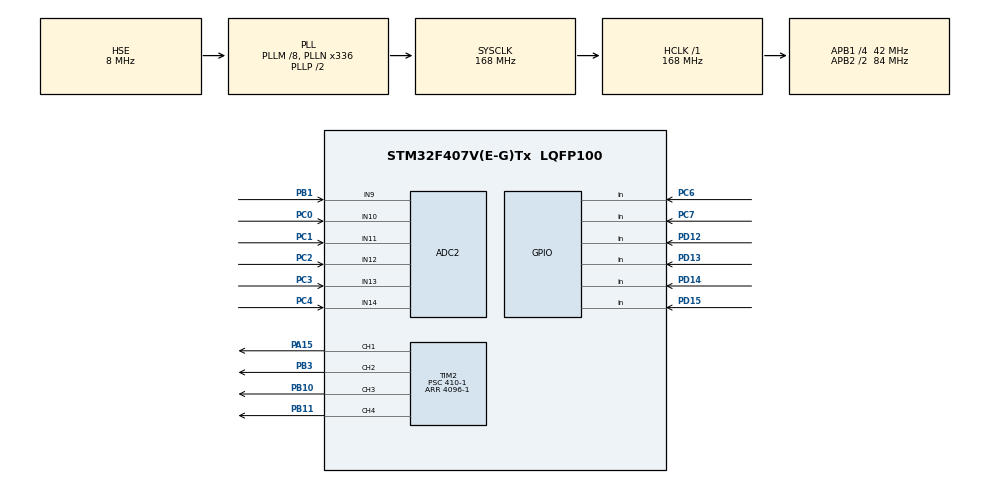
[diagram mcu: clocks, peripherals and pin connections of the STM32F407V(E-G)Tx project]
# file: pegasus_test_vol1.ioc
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ADC2.Channel-1\#ChannelRegularConversion=ADC_CHANNEL_14
ADC2.Channel-2\#ChannelRegularConversion=ADC_CHANNEL_13
ADC2.Channel-3\#ChannelRegularConversion=ADC_CHANNEL_12
ADC2.Channel-4\#ChannelRegularConversion=ADC_CHANNEL_11
ADC2.Channel-5\#ChannelRegularConversion=ADC_CHANNEL_10
ADC2.Channel-6\#ChannelRegularConversion=ADC_CHANNEL_9
ADC2.ContinuousConvMode=DISABLE
ADC2.DMAContinuousRequests=ENABLE
ADC2.DiscontinuousConvMode=DISABLE
ADC2.NbrOfConversion=6
ADC2.NbrOfConversionFlag=1
ADC2.Rank-1\#ChannelRegularConversion=1
ADC2.Rank-2\#ChannelRegularConversion=2
ADC2.Rank-3\#ChannelRegularConversion=3
ADC2.Rank-4\#ChannelRegularConversion=4
ADC2.Rank-5\#ChannelRegularConversion=5
ADC2.Rank-6\#ChannelRegularConversion=6
ADC2.SamplingTime-1\#ChannelRegularConversion=ADC_SAMPLETIME_3CYCLES
ADC2.SamplingTime-2\#ChannelRegularConversion=ADC_SAMPLETIME_3CYCLES
ADC2.SamplingTime-3\#ChannelRegularConversion=ADC_SAMPLETIME_3CYCLES
ADC2.SamplingTime-4\#ChannelRegularConversion=ADC_SAMPLETIME_3CYCLES
ADC2.SamplingTime-5\#ChannelRegularConversion=ADC_SAMPLETIME_3CYCLES
ADC2.SamplingTime-6\#ChannelRegularConversion=ADC_SAMPLETIME_3CYCLES
ADC2.ScanConvMode=ENABLE
Dma.ADC2.0.Direction=DMA_PERIPH_TO_MEMORY
Dma.ADC2.0.FIFOMode=DMA_FIFOMODE_DISABLE
Dma.ADC2.0.Instance=DMA2_Stream2
Dma.ADC2.0.MemDataAlignment=DMA_MDATAALIGN_WORD
Dma.ADC2.0.MemInc=DMA_MINC_ENABLE
Dma.ADC2.0.Mode=DMA_NORMAL
Dma.ADC2.0.PeriphDataAlignment=DMA_PDATAALIGN_WORD
Dma.ADC2.0.PeriphInc=DMA_PINC_DISABLE
Dma.ADC2.0.Priority=DMA_PRIORITY_LOW
Dma.Request0=ADC2
Mcu.Family=STM32F4
Mcu.Name=STM32F407V(E-G)Tx
Mcu.Package=LQFP100
NVIC.DMA2_Stream2_IRQn=true\:0\:0\:false\:false\:true\:false\:true\:true
NVIC.PriorityGroup=NVIC_PRIORITYGROUP_0
PA13.Mode=Serial_Wire
PA13.Signal=SYS_JTMS-SWDIO
PA14.Mode=Serial_Wire
PA14.Signal=SYS_JTCK-SWCLK
PA15.Signal=S_TIM2_CH1_ETR
PB1.Signal=ADCx_IN9
PB10.Signal=S_TIM2_CH3
PB11.Signal=S_TIM2_CH4
PB3.Signal=S_TIM2_CH2
PC0.Signal=ADCx_IN10
PC1.Signal=ADCx_IN11
PC2.Signal=ADCx_IN12
PC3.Signal=ADCx_IN13
PC4.Signal=ADCx_IN14
PC6.Signal=GPIO_Input
PC7.Signal=GPIO_Input
PD12.Signal=GPIO_Input
PD13.Signal=GPIO_Input
PD14.Signal=GPIO_Input
PD15.Signal=GPIO_Input
PH0-OSC_IN.Mode=HSE-External-Oscillator
PH0-OSC_IN.Signal=RCC_OSC_IN
PH1-OSC_OUT.Mode=HSE-External-Oscillator
PH1-OSC_OUT.Signal=RCC_OSC_OUT
ProjectManager.HeapSize=0x200
ProjectManager.StackSize=0x400
ProjectManager.TargetToolchain=STM32CubeIDE
RCC.48MHZClocksFreq_Value=48000000
RCC.AHBFreq_Value=168000000
RCC.APB1CLKDivider=RCC_HCLK_DIV4
RCC.APB1Freq_Value=42000000
RCC.APB1TimFreq_Value=84000000
RCC.APB2CLKDivider=RCC_HCLK_DIV2
RCC.APB2Freq_Value=84000000
RCC.APB2TimFreq_Value=168000000
RCC.CortexFreq_Value=168000000
RCC.HCLKFreq_Value=168000000
RCC.HSE_VALUE=8000000
RCC.HSI_VALUE=16000000
RCC.LSE_VALUE=32768
RCC.PLLM=8
RCC.PLLN=336
RCC.PLLQ=7
RCC.PLLSourceVirtual=RCC_PLLSOURCE_HSE
RCC.SYSCLKFreq_VALUE=168000000
RCC.SYSCLKSource=RCC_SYSCLKSOURCE_PLLCLK
RCC.VCOOutputFreq_Value=336000000
SH.ADCx_IN10.0=ADC2_IN10,IN10
SH.ADCx_IN11.0=ADC2_IN11,IN11
SH.ADCx_IN12.0=ADC2_IN12,IN12
SH.ADCx_IN13.0=ADC2_IN13,IN13
SH.ADCx_IN14.0=ADC2_IN14,IN14
SH.ADCx_IN9.0=ADC2_IN9,IN9
SH.S_TIM2_CH1_ETR.0=TIM2_CH1,PWM Generation1 CH1
SH.S_TIM2_CH2.0=TIM2_CH2,PWM Generation2 CH2
SH.S_TIM2_CH3.0=TIM2_CH3,PWM Generation3 CH3
SH.S_TIM2_CH4.0=TIM2_CH4,PWM Generation4 CH4
TIM2.AutoReloadPreload=TIM_AUTORELOAD_PRELOAD_ENABLE
TIM2.Channel-PWM\ Generation1\ CH1=TIM_CHANNEL_1
TIM2.Channel-PWM\ Generation2\ CH2=TIM_CHANNEL_2
TIM2.Channel-PWM\ Generation3\ CH3=TIM_CHANNEL_3
TIM2.Channel-PWM\ Generation4\ CH4=TIM_CHANNEL_4
TIM2.Period=4096-1
TIM2.Prescaler=410-1
board=STM32F407G-DISC1

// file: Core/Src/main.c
/* USER CODE BEGIN Header */
/**
  ******************************************************************************
  * @file           : main.c
  * @brief          : Main program body
  ******************************************************************************
  * @attention
  *
  * Copyright (c) 2023 STMicroelectronics.
  * All rights reserved.
  *
  * This software is licensed under terms that can be found in the LICENSE file
  * in the root directory of this software component.
  * If no LICENSE file comes with this software, it is provided AS-IS.
  *
  ******************************************************************************
  */
/* USER CODE END Header */
#include "main.h"
#include <math.h>

ADC_HandleTypeDef hadc2;
DMA_HandleTypeDef hdma_adc2;

TIM_HandleTypeDef htim2;

void SystemClock_Config(void);
static void MX_GPIO_Init(void);
static void MX_DMA_Init(void);
static void MX_ADC2_Init(void);
static void MX_TIM2_Init(void);
/* USER CODE BEGIN PFP */
uint32_t readvalue[5];
float dutycycle=0;
/* USER CODE END PFP */

int main(void)
{

  /* MCU Configuration--------------------------------------------------------*/

  /* Reset of all peripherals, Initializes the Flash interface and the Systick. */
  HAL_Init();

  /* Configure the system clock */
  SystemClock_Config();

  /* Initialize all configured peripherals */
  MX_GPIO_Init();
  MX_DMA_Init();
  MX_ADC2_Init();
  MX_TIM2_Init();
  /* USER CODE BEGIN 2 */
  HAL_TIM_PWM_Start(&htim2, TIM_CHANNEL_1);
  HAL_TIM_PWM_Start(&htim2, TIM_CHANNEL_2);
  HAL_TIM_PWM_Start(&htim2, TIM_CHANNEL_3);
  HAL_TIM_PWM_Start(&htim2, TIM_CHANNEL_4);

  /* USER CODE END 2 */

  /* Infinite loop */
  while (1)
  {
	  HAL_ADC_Start_DMA(&hadc2,readvalue,5);
	  dutycycle= (readvalue[1]/19)+215;
	  if(dutycycle>409)
		  dutycycle=409;
	  TIM2->CCR1 = dutycycle;
	  HAL_Delay(40);
  }
}

void SystemClock_Config(void)
{
  RCC_OscInitTypeDef RCC_OscInitStruct = {0};
  RCC_ClkInitTypeDef RCC_ClkInitStruct = {0};

  /** Configure the main internal regulator output voltage
  */
  __HAL_RCC_PWR_CLK_ENABLE();
  __HAL_PWR_VOLTAGESCALING_CONFIG(PWR_REGULATOR_VOLTAGE_SCALE1);

  /** Initializes the RCC Oscillators according to the specified parameters
  * in the RCC_OscInitTypeDef structure.
  */
  RCC_OscInitStruct.OscillatorType = RCC_OSCILLATORTYPE_HSE;
  RCC_OscInitStruct.HSEState = RCC_HSE_ON;
  RCC_OscInitStruct.PLL.PLLState = RCC_PLL_ON;
  RCC_OscInitStruct.PLL.PLLSource = RCC_PLLSOURCE_HSE;
  RCC_OscInitStruct.PLL.PLLM = 8;
  RCC_OscInitStruct.PLL.PLLN = 336;
  RCC_OscInitStruct.PLL.PLLP = RCC_PLLP_DIV2;
  RCC_OscInitStruct.PLL.PLLQ = 7;
  if (HAL_RCC_OscConfig(&RCC_OscInitStruct) != HAL_OK)
  {
    Error_Handler();
  }

  /** Initializes the CPU, AHB and APB buses clocks
  */
  RCC_ClkInitStruct.ClockType = RCC_CLOCKTYPE_HCLK|RCC_CLOCKTYPE_SYSCLK
                              |RCC_CLOCKTYPE_PCLK1|RCC_CLOCKTYPE_PCLK2;
  RCC_ClkInitStruct.SYSCLKSource = RCC_SYSCLKSOURCE_PLLCLK;
  RCC_ClkInitStruct.AHBCLKDivider = RCC_SYSCLK_DIV1;
  RCC_ClkInitStruct.APB1CLKDivider = RCC_HCLK_DIV4;
  RCC_ClkInitStruct.APB2CLKDivider = RCC_HCLK_DIV2;

  if (HAL_RCC_ClockConfig(&RCC_ClkInitStruct, FLASH_LATENCY_5) != HAL_OK)
  {
    Error_Handler();
  }
}

static void MX_ADC2_Init(void)
{

  ADC_ChannelConfTypeDef sConfig = {0};

  /** Configure the global features of the ADC (Clock, Resolution, Data Alignment and number of conversion)
  */
  hadc2.Instance = ADC2;
  hadc2.Init.ClockPrescaler = ADC_CLOCK_SYNC_PCLK_DIV4;
  hadc2.Init.Resolution = ADC_RESOLUTION_12B;
  hadc2.Init.ScanConvMode = ENABLE;
  hadc2.Init.ContinuousConvMode = DISABLE;
  hadc2.Init.DiscontinuousConvMode = DISABLE;
  hadc2.Init.ExternalTrigConvEdge = ADC_EXTERNALTRIGCONVEDGE_NONE;
  hadc2.Init.ExternalTrigConv = ADC_SOFTWARE_START;
  hadc2.Init.DataAlign = ADC_DATAALIGN_RIGHT;
  hadc2.Init.NbrOfConversion = 6;
  hadc2.Init.DMAContinuousRequests = ENABLE;
  hadc2.Init.EOCSelection = ADC_EOC_SINGLE_CONV;
  if (HAL_ADC_Init(&hadc2) != HAL_OK)
  {
    Error_Handler();
  }

  /** Configure for the selected ADC regular channel its corresponding rank in the sequencer and its sample time.
  */
  sConfig.Channel = ADC_CHANNEL_14;
  sConfig.Rank = 1;
  sConfig.SamplingTime = ADC_SAMPLETIME_3CYCLES;
  if (HAL_ADC_ConfigChannel(&hadc2, &sConfig) != HAL_OK)
  {
    Error_Handler();
  }

  /** Configure for the selected ADC regular channel its corresponding rank in the sequencer and its sample time.
  */
  sConfig.Channel = ADC_CHANNEL_13;
  sConfig.Rank = 2;
  if (HAL_ADC_ConfigChannel(&hadc2, &sConfig) != HAL_OK)
  {
    Error_Handler();
  }

  /** Configure for the selected ADC regular channel its corresponding rank in the sequencer and its sample time.
  */
  sConfig.Channel = ADC_CHANNEL_12;
  sConfig.Rank = 3;
  if (HAL_ADC_ConfigChannel(&hadc2, &sConfig) != HAL_OK)
  {
    Error_Handler();
  }

  /** Configure for the selected ADC regular channel its corresponding rank in the sequencer and its sample time.
  */
  sConfig.Channel = ADC_CHANNEL_11;
  sConfig.Rank = 4;
  if (HAL_ADC_ConfigChannel(&hadc2, &sConfig) != HAL_OK)
  {
    Error_Handler();
  }

  /** Configure for the selected ADC regular channel its corresponding rank in the sequencer and its sample time.
  */
  sConfig.Channel = ADC_CHANNEL_10;
  sConfig.Rank = 5;
  if (HAL_ADC_ConfigChannel(&hadc2, &sConfig) != HAL_OK)
  {
    Error_Handler();
  }

  /** Configure for the selected ADC regular channel its corresponding rank in the sequencer and its sample time.
  */
  sConfig.Channel = ADC_CHANNEL_9;
  sConfig.Rank = 6;
  if (HAL_ADC_ConfigChannel(&hadc2, &sConfig) != HAL_OK)
  {
    Error_Handler();
  }

}

static void MX_TIM2_Init(void)
{

  TIM_MasterConfigTypeDef sMasterConfig = {0};
  TIM_OC_InitTypeDef sConfigOC = {0};

  htim2.Instance = TIM2;
  htim2.Init.Prescaler = 410-1;
  htim2.Init.CounterMode = TIM_COUNTERMODE_UP;
  htim2.Init.Period = 4096-1;
  htim2.Init.ClockDivision = TIM_CLOCKDIVISION_DIV1;
  htim2.Init.AutoReloadPreload = TIM_AUTORELOAD_PRELOAD_ENABLE;
  if (HAL_TIM_PWM_Init(&htim2) != HAL_OK)
  {
    Error_Handler();
  }
  sMasterConfig.MasterOutputTrigger = TIM_TRGO_RESET;
  sMasterConfig.MasterSlaveMode = TIM_MASTERSLAVEMODE_DISABLE;
  if (HAL_TIMEx_MasterConfigSynchronization(&htim2, &sMasterConfig) != HAL_OK)
  {
    Error_Handler();
  }
  sConfigOC.OCMode = TIM_OCMODE_PWM1;
  sConfigOC.Pulse = 0;
  sConfigOC.OCPolarity = TIM_OCPOLARITY_HIGH;
  sConfigOC.OCFastMode = TIM_OCFAST_DISABLE;
  if (HAL_TIM_PWM_ConfigChannel(&htim2, &sConfigOC, TIM_CHANNEL_1) != HAL_OK)
  {
    Error_Handler();
  }
  if (HAL_TIM_PWM_ConfigChannel(&htim2, &sConfigOC, TIM_CHANNEL_2) != HAL_OK)
  {
    Error_Handler();
  }
  if (HAL_TIM_PWM_ConfigChannel(&htim2, &sConfigOC, TIM_CHANNEL_3) != HAL_OK)
  {
    Error_Handler();
  }
  if (HAL_TIM_PWM_ConfigChannel(&htim2, &sConfigOC, TIM_CHANNEL_4) != HAL_OK)
  {
    Error_Handler();
  }
  HAL_TIM_MspPostInit(&htim2);

}

static void MX_DMA_Init(void)
{

  /* DMA controller clock enable */
  __HAL_RCC_DMA2_CLK_ENABLE();

  /* DMA interrupt init */
  /* DMA2_Stream2_IRQn interrupt configuration */
  HAL_NVIC_SetPriority(DMA2_Stream2_IRQn, 0, 0);
  HAL_NVIC_EnableIRQ(DMA2_Stream2_IRQn);

}

static void MX_GPIO_Init(void)
{
  GPIO_InitTypeDef GPIO_InitStruct = {0};

  /* GPIO Ports Clock Enable */
  __HAL_RCC_GPIOH_CLK_ENABLE();
  __HAL_RCC_GPIOC_CLK_ENABLE();
  __HAL_RCC_GPIOB_CLK_ENABLE();
  __HAL_RCC_GPIOD_CLK_ENABLE();
  __HAL_RCC_GPIOA_CLK_ENABLE();

  /*Configure GPIO pins : PD12 PD13 PD14 PD15 */
  GPIO_InitStruct.Pin = GPIO_PIN_12|GPIO_PIN_13|GPIO_PIN_14|GPIO_PIN_15;
  GPIO_InitStruct.Mode = GPIO_MODE_INPUT;
  GPIO_InitStruct.Pull = GPIO_NOPULL;
  HAL_GPIO_Init(GPIOD, &GPIO_InitStruct);

  /*Configure GPIO pins : PC6 PC7 */
  GPIO_InitStruct.Pin = GPIO_PIN_6|GPIO_PIN_7;
  GPIO_InitStruct.Mode = GPIO_MODE_INPUT;
  GPIO_InitStruct.Pull = GPIO_NOPULL;
  HAL_GPIO_Init(GPIOC, &GPIO_InitStruct);

}

void Error_Handler(void)
{
  __disable_irq();
  while (1)
  {
  }
}
